AUTOSAR XML (schema 4-3-0)
package /ComponentTypes
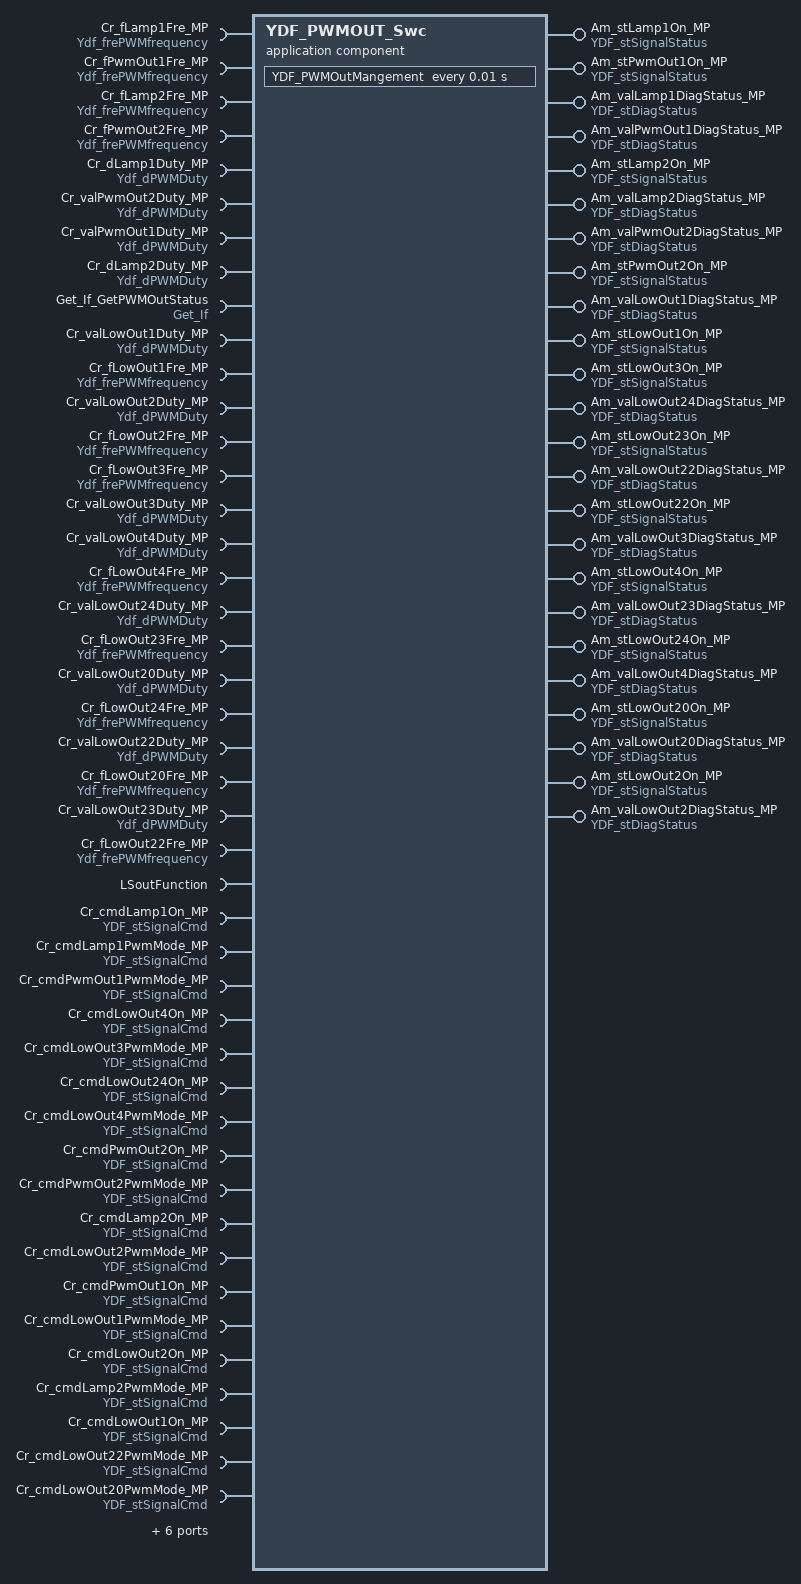
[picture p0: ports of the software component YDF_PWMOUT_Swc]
  application sw component type YDF_PWMOUT_Swc
    provide port Am_stLamp1On_MP: nonqueued-sender-com-spec{data-element=SignalStatus, init-value=0}, provided-interface=YDF_stSignalStatus
    8 x require port:
      Cr_fLamp1Fre_MP: nonqueued-receiver-com-spec{data-element=PWMfrequency, init-value=0}, required-interface=Ydf_frePWMfrequency
      Cr_fPwmOut1Fre_MP: nonqueued-receiver-com-spec{data-element=PWMfrequency, init-value=0}, required-interface=Ydf_frePWMfrequency
      Cr_fLamp2Fre_MP: nonqueued-receiver-com-spec{data-element=PWMfrequency, filter=data-filter-type=ALWAYS, init-value=0}, required-interface=Ydf_frePWMfrequency
      Cr_fPwmOut2Fre_MP: nonqueued-receiver-com-spec{data-element=PWMfrequency, init-value=0}, required-interface=Ydf_frePWMfrequency
      Cr_dLamp1Duty_MP: nonqueued-receiver-com-spec{data-element=PWMDuty, filter=data-filter-type=ALWAYS, init-value=0}, required-interface=Ydf_dPWMDuty
      Cr_valPwmOut2Duty_MP: nonqueued-receiver-com-spec{data-element=PWMDuty, filter=data-filter-type=ALWAYS, init-value=0}, required-interface=Ydf_dPWMDuty
      Cr_valPwmOut1Duty_MP: nonqueued-receiver-com-spec{data-element=PWMDuty, filter=data-filter-type=ALWAYS, init-value=0}, required-interface=Ydf_dPWMDuty
      Cr_dLamp2Duty_MP: nonqueued-receiver-com-spec{data-element=PWMDuty, filter=data-filter-type=ALWAYS, init-value=0}, required-interface=Ydf_dPWMDuty
    provide port Am_stPwmOut1On_MP: nonqueued-sender-com-spec{data-element=SignalStatus, init-value=0}, provided-interface=YDF_stSignalStatus
    provide port Am_valLamp1DiagStatus_MP: nonqueued-sender-com-spec{data-element=DiagStatus, init-value=0}, provided-interface=YDF_stDiagStatus
    provide port Am_valPwmOut1DiagStatus_MP: nonqueued-sender-com-spec{data-element=DiagStatus, init-value=0}, provided-interface=YDF_stDiagStatus
    require port Get_If_GetPWMOutStatus: required-interface=Get_If
      required-com-specs:
        Get_Ad_Result
        Get_io_inResult
        Get_BTS_OutResult
        Get_CAN_ActiveInf
        Icu_17_GtmCcu6_PWMIN_CH{1..4}
        Icu_17_GtmCcu6_PWMIN_PWMSCB1
        Icu_17_GtmCcu6_PWMIN_PWMSCB2
        Icu_17_GtmCcu6_PWMIN_LAMPSCB1
        Icu_17_GtmCcu6_PWMIN_LAMPSCB2
        Get_Bottom_Ver
        Get_SentData
        Get_Level_OutResult
        Get_PwmOrLevel_OutResult
        Get_Motor_OutResult
    4 x provide port:
      Am_stLamp2On_MP: nonqueued-sender-com-spec{data-element=SignalStatus, init-value=0}, provided-interface=YDF_stSignalStatus
      Am_valLamp2DiagStatus_MP: nonqueued-sender-com-spec{data-element=DiagStatus, init-value=0}, provided-interface=YDF_stDiagStatus
      Am_valPwmOut2DiagStatus_MP: nonqueued-sender-com-spec{data-element=DiagStatus, init-value=0}, provided-interface=YDF_stDiagStatus
      Am_stPwmOut2On_MP: nonqueued-sender-com-spec{data-element=SignalStatus, init-value=0}, provided-interface=YDF_stSignalStatus
    17 x require port:
      Cr_valLowOut1Duty_MP: nonqueued-receiver-com-spec{data-element=PWMDuty, filter=data-filter-type=ALWAYS, init-value=0}, required-interface=Ydf_dPWMDuty
      Cr_fLowOut1Fre_MP: nonqueued-receiver-com-spec{data-element=PWMfrequency, init-value=0}, required-interface=Ydf_frePWMfrequency
      Cr_valLowOut2Duty_MP: nonqueued-receiver-com-spec{data-element=PWMDuty, filter=data-filter-type=ALWAYS, init-value=0}, required-interface=Ydf_dPWMDuty
      Cr_fLowOut2Fre_MP: nonqueued-receiver-com-spec{data-element=PWMfrequency, init-value=0}, required-interface=Ydf_frePWMfrequency
      Cr_fLowOut3Fre_MP: nonqueued-receiver-com-spec{data-element=PWMfrequency, init-value=0}, required-interface=Ydf_frePWMfrequency
      Cr_valLowOut3Duty_MP: nonqueued-receiver-com-spec{data-element=PWMDuty, filter=data-filter-type=ALWAYS, init-value=0}, required-interface=Ydf_dPWMDuty
      Cr_valLowOut4Duty_MP: nonqueued-receiver-com-spec{data-element=PWMDuty, filter=data-filter-type=ALWAYS, init-value=0}, required-interface=Ydf_dPWMDuty
      Cr_fLowOut4Fre_MP: nonqueued-receiver-com-spec{data-element=PWMfrequency, init-value=0}, required-interface=Ydf_frePWMfrequency
      Cr_valLowOut24Duty_MP: nonqueued-receiver-com-spec{data-element=PWMDuty, filter=data-filter-type=ALWAYS, init-value=0}, required-interface=Ydf_dPWMDuty
      Cr_fLowOut23Fre_MP: nonqueued-receiver-com-spec{data-element=PWMfrequency, init-value=0}, required-interface=Ydf_frePWMfrequency
      Cr_valLowOut20Duty_MP: nonqueued-receiver-com-spec{data-element=PWMDuty, filter=data-filter-type=ALWAYS, init-value=0}, required-interface=Ydf_dPWMDuty
      Cr_fLowOut24Fre_MP: nonqueued-receiver-com-spec{data-element=PWMfrequency, init-value=0}, required-interface=Ydf_frePWMfrequency
      Cr_valLowOut22Duty_MP: nonqueued-receiver-com-spec{data-element=PWMDuty, filter=data-filter-type=ALWAYS, init-value=0}, required-interface=Ydf_dPWMDuty
      Cr_fLowOut20Fre_MP: nonqueued-receiver-com-spec{data-element=PWMfrequency, init-value=0}, required-interface=Ydf_frePWMfrequency
      Cr_valLowOut23Duty_MP: nonqueued-receiver-com-spec{data-element=PWMDuty, filter=data-filter-type=ALWAYS, init-value=0}, required-interface=Ydf_dPWMDuty
      Cr_fLowOut22Fre_MP: nonqueued-receiver-com-spec{data-element=PWMfrequency, init-value=0}, required-interface=Ydf_frePWMfrequency
      LSoutFunction: required-interface=LSoutFunction
        required-com-specs:
          Lowout{1..4}_Function
          Lowout20_Function
          Lowout{22..24}_Function
          Lowout_Lamp1_Function
          Lowout_Lamp2_Function
          Lowout_PWMOUT1_Function
          Lowout_PWMOUT2_Function
          Lowout{5..19}_Function
          Lowout21_Function
    16 x provide port:
      Am_valLowOut1DiagStatus_MP: nonqueued-sender-com-spec{data-element=DiagStatus, init-value=0}, provided-interface=YDF_stDiagStatus
      Am_stLowOut1On_MP: nonqueued-sender-com-spec{data-element=SignalStatus, init-value=0}, provided-interface=YDF_stSignalStatus
      Am_stLowOut3On_MP: nonqueued-sender-com-spec{data-element=SignalStatus, init-value=0}, provided-interface=YDF_stSignalStatus
      Am_valLowOut24DiagStatus_MP: nonqueued-sender-com-spec{data-element=DiagStatus, init-value=0}, provided-interface=YDF_stDiagStatus
      Am_stLowOut23On_MP: nonqueued-sender-com-spec{data-element=SignalStatus, init-value=0}, provided-interface=YDF_stSignalStatus
      Am_valLowOut22DiagStatus_MP: nonqueued-sender-com-spec{data-element=DiagStatus, init-value=0}, provided-interface=YDF_stDiagStatus
      Am_stLowOut22On_MP: nonqueued-sender-com-spec{data-element=SignalStatus, init-value=0}, provided-interface=YDF_stSignalStatus
      Am_valLowOut3DiagStatus_MP: nonqueued-sender-com-spec{data-element=DiagStatus, init-value=0}, provided-interface=YDF_stDiagStatus
      Am_stLowOut4On_MP: nonqueued-sender-com-spec{data-element=SignalStatus, init-value=0}, provided-interface=YDF_stSignalStatus
      Am_valLowOut23DiagStatus_MP: nonqueued-sender-com-spec{data-element=DiagStatus, init-value=0}, provided-interface=YDF_stDiagStatus
      Am_stLowOut24On_MP: nonqueued-sender-com-spec{data-element=SignalStatus, init-value=0}, provided-interface=YDF_stSignalStatus
      Am_valLowOut4DiagStatus_MP: nonqueued-sender-com-spec{data-element=DiagStatus, init-value=0}, provided-interface=YDF_stDiagStatus
      Am_stLowOut20On_MP: nonqueued-sender-com-spec{data-element=SignalStatus, init-value=0}, provided-interface=YDF_stSignalStatus
      Am_valLowOut20DiagStatus_MP: nonqueued-sender-com-spec{data-element=DiagStatus, init-value=0}, provided-interface=YDF_stDiagStatus
      Am_stLowOut2On_MP: nonqueued-sender-com-spec{data-element=SignalStatus, init-value=0}, provided-interface=YDF_stSignalStatus
      Am_valLowOut2DiagStatus_MP: nonqueued-sender-com-spec{data-element=DiagStatus, init-value=0}, provided-interface=YDF_stDiagStatus
    24 x require port, all with nonqueued-receiver-com-spec{data-element=SignalCmd, init-value=0}, required-interface=YDF_stSignalCmd:
      Cr_cmdLamp1On_MP
      Cr_cmdLamp1PwmMode_MP
      Cr_cmdPwmOut1PwmMode_MP
      Cr_cmdLowOut4On_MP
      Cr_cmdLowOut3PwmMode_MP
      Cr_cmdLowOut24On_MP
      Cr_cmdLowOut4PwmMode_MP
      Cr_cmdPwmOut2On_MP
      Cr_cmdPwmOut2PwmMode_MP
      Cr_cmdLamp2On_MP
      Cr_cmdLowOut2PwmMode_MP
      Cr_cmdPwmOut1On_MP
      Cr_cmdLowOut1PwmMode_MP
      Cr_cmdLowOut2On_MP
      Cr_cmdLamp2PwmMode_MP
      Cr_cmdLowOut1On_MP
      Cr_cmdLowOut22PwmMode_MP
      Cr_cmdLowOut20PwmMode_MP
      Cr_cmdLowOut23PwmMode_MP
      Cr_cmdLowOut24PwmMode_MP
      Cr_cmdLowOut20On_MP
      Cr_cmdLowOut22On_MP
      Cr_cmdLowOut23On_MP
      Cr_cmdLowOut3On_MP
    behavior YDF_PWMOUT_Swc_InternalBehavior
      timing event TMT_YDF_PWMOutMangement: start-on-event=YDF_PWMOutMangement, period=0.01
      runnable YDF_PWMOutMangement
        data-receive-point-by-arguments:
          48 x access:
            REC_Cr_dLamp1Duty_MP_PWMDuty: accessed-variable=Cr_dLamp1Duty_MP.PWMDuty
            REC_Cr_dLamp2Duty_MP_PWMDuty: accessed-variable=Cr_dLamp2Duty_MP.PWMDuty
            REC_Cr_fLamp1Fre_MP_PWMfrequency: accessed-variable=Cr_fLamp1Fre_MP.PWMfrequency
            REC_Cr_fLamp2Fre_MP_PWMfrequency: accessed-variable=Cr_fLamp2Fre_MP.PWMfrequency
            REC_Cr_fLowOut1Fre_MP_PWMfrequency: accessed-variable=Cr_fLowOut1Fre_MP.PWMfrequency
            REC_Cr_fLowOut20Fre_MP_PWMfrequency: accessed-variable=Cr_fLowOut20Fre_MP.PWMfrequency
            REC_Cr_fLowOut{22..24}Fre_MP_PWMfrequency: accessed-variable=Cr_fLowOut{22..24}Fre_MP.PWMfrequency
            REC_Cr_fLowOut{2..4}Fre_MP_PWMfrequency: accessed-variable=Cr_fLowOut{2..4}Fre_MP.PWMfrequency
            REC_Cr_fPwmOut1Fre_MP_PWMfrequency: accessed-variable=Cr_fPwmOut1Fre_MP.PWMfrequency
            REC_Cr_fPwmOut2Fre_MP_PWMfrequency: accessed-variable=Cr_fPwmOut2Fre_MP.PWMfrequency
            REC_Cr_valLowOut1Duty_MP_PWMDuty: accessed-variable=Cr_valLowOut1Duty_MP.PWMDuty
            REC_Cr_valLowOut20Duty_MP_PWMDuty: accessed-variable=Cr_valLowOut20Duty_MP.PWMDuty
            REC_Cr_valLowOut{22..24}Duty_MP_PWMDuty: accessed-variable=Cr_valLowOut{22..24}Duty_MP.PWMDuty
            REC_Cr_valLowOut{2..4}Duty_MP_PWMDuty: accessed-variable=Cr_valLowOut{2..4}Duty_MP.PWMDuty
            REC_Cr_valPwmOut1Duty_MP_PWMDuty: accessed-variable=Cr_valPwmOut1Duty_MP.PWMDuty
            REC_Cr_valPwmOut2Duty_MP_PWMDuty: accessed-variable=Cr_valPwmOut2Duty_MP.PWMDuty
            REC_Cr_cmdLamp1On_MP_SignalCmd: accessed-variable=Cr_cmdLamp1On_MP.SignalCmd
            REC_Cr_cmdLamp1PwmMode_MP_SignalCmd: accessed-variable=Cr_cmdLamp1PwmMode_MP.SignalCmd
            REC_Cr_cmdLamp2On_MP_SignalCmd: accessed-variable=Cr_cmdLamp2On_MP.SignalCmd
            REC_Cr_cmdLamp2PwmMode_MP_SignalCmd: accessed-variable=Cr_cmdLamp2PwmMode_MP.SignalCmd
            REC_Cr_cmdLowOut1On_MP_SignalCmd: accessed-variable=Cr_cmdLowOut1On_MP.SignalCmd
            REC_Cr_cmdLowOut1PwmMode_MP_SignalCmd: accessed-variable=Cr_cmdLowOut1PwmMode_MP.SignalCmd
            REC_Cr_cmdLowOut20On_MP_SignalCmd: accessed-variable=Cr_cmdLowOut20On_MP.SignalCmd
            REC_Cr_cmdLowOut20PwmMode_MP_SignalCmd: accessed-variable=Cr_cmdLowOut20PwmMode_MP.SignalCmd
            REC_Cr_cmdLowOut22On_MP_SignalCmd: accessed-variable=Cr_cmdLowOut22On_MP.SignalCmd
            REC_Cr_cmdLowOut22PwmMode_MP_SignalCmd: accessed-variable=Cr_cmdLowOut22PwmMode_MP.SignalCmd
            REC_Cr_cmdLowOut23On_MP_SignalCmd: accessed-variable=Cr_cmdLowOut23On_MP.SignalCmd
            REC_Cr_cmdLowOut23PwmMode_MP_SignalCmd: accessed-variable=Cr_cmdLowOut23PwmMode_MP.SignalCmd
            REC_Cr_cmdLowOut24On_MP_SignalCmd: accessed-variable=Cr_cmdLowOut24On_MP.SignalCmd
            REC_Cr_cmdLowOut24PwmMode_MP_SignalCmd: accessed-variable=Cr_cmdLowOut24PwmMode_MP.SignalCmd
            REC_Cr_cmdLowOut2On_MP_SignalCmd: accessed-variable=Cr_cmdLowOut2On_MP.SignalCmd
            REC_Cr_cmdLowOut2PwmMode_MP_SignalCmd: accessed-variable=Cr_cmdLowOut2PwmMode_MP.SignalCmd
            REC_Cr_cmdLowOut3On_MP_SignalCmd: accessed-variable=Cr_cmdLowOut3On_MP.SignalCmd
            REC_Cr_cmdLowOut3PwmMode_MP_SignalCmd: accessed-variable=Cr_cmdLowOut3PwmMode_MP.SignalCmd
            REC_Cr_cmdLowOut4On_MP_SignalCmd: accessed-variable=Cr_cmdLowOut4On_MP.SignalCmd
            REC_Cr_cmdLowOut4PwmMode_MP_SignalCmd: accessed-variable=Cr_cmdLowOut4PwmMode_MP.SignalCmd
            REC_Cr_cmdPwmOut1On_MP_SignalCmd: accessed-variable=Cr_cmdPwmOut1On_MP.SignalCmd
            REC_Cr_cmdPwmOut1PwmMode_MP_SignalCmd: accessed-variable=Cr_cmdPwmOut1PwmMode_MP.SignalCmd
            REC_Cr_cmdPwmOut2On_MP_SignalCmd: accessed-variable=Cr_cmdPwmOut2On_MP.SignalCmd
            REC_Cr_cmdPwmOut2PwmMode_MP_SignalCmd: accessed-variable=Cr_cmdPwmOut2PwmMode_MP.SignalCmd
        data-send-points:
          24 x access:
            SEND_Am_fLamp1On_MP_SignalStatus: accessed-variable=Am_stLamp1On_MP.SignalStatus
            SEND_Am_fLamp2On_MP_SignalStatus: accessed-variable=Am_stLamp2On_MP.SignalStatus
            SEND_Am_fLowOut1On_MP_SignalStatus: accessed-variable=Am_stLowOut1On_MP.SignalStatus
            SEND_Am_fLowOut20On_MP_SignalStatus: accessed-variable=Am_stLowOut20On_MP.SignalStatus
            SEND_Am_fLowOut{22..24}On_MP_SignalStatus: accessed-variable=Am_stLowOut{22..24}On_MP.SignalStatus
            SEND_Am_fLowOut{2..4}On_MP_SignalStatus: accessed-variable=Am_stLowOut{2..4}On_MP.SignalStatus
            SEND_Am_fPwmOut1On_MP_SignalStatus: accessed-variable=Am_stPwmOut1On_MP.SignalStatus
            SEND_Am_fPwmOut2On_MP_SignalStatus: accessed-variable=Am_stPwmOut2On_MP.SignalStatus
            SEND_Am_valLamp1DiagStatus_MP_DiagStatus: accessed-variable=Am_valLamp1DiagStatus_MP.DiagStatus
            SEND_Am_valLamp2DiagStatus_MP_DiagStatus: accessed-variable=Am_valLamp2DiagStatus_MP.DiagStatus
            SEND_Am_valLowOut1DiagStatus_MP_DiagStatus: accessed-variable=Am_valLowOut1DiagStatus_MP.DiagStatus
            SEND_Am_valLowOut20DiagStatus_MP_DiagStatus: accessed-variable=Am_valLowOut20DiagStatus_MP.DiagStatus
            SEND_Am_valLowOut{22..24}DiagStatus_MP_DiagStatus: accessed-variable=Am_valLowOut{22..24}DiagStatus_MP.DiagStatus
            SEND_Am_valLowOut{2..4}DiagStatus_MP_DiagStatus: accessed-variable=Am_valLowOut{2..4}DiagStatus_MP.DiagStatus
            SEND_Am_valPwmOut1DiagStatus_MP_DiagStatus: accessed-variable=Am_valPwmOut1DiagStatus_MP.DiagStatus
            SEND_Am_valPwmOut2DiagStatus_MP_DiagStatus: accessed-variable=Am_valPwmOut2DiagStatus_MP.DiagStatus
        13 x sync call:
          SC_Get_If_GetPWMOutStatus_Get_PwmOrLevel_OutResult: operation=Get_If_GetPWMOutStatus.Get_PwmOrLevel_OutResult
          SC_LSoutFunction_Lowout_Lamp1_Function: operation=LSoutFunction.Lowout_Lamp1_Function
          SC_LSoutFunction_Lowout_Lamp2_Function: operation=LSoutFunction.Lowout_Lamp2_Function
          SC_LSoutFunction_Lowout_PWMOUT1_Function: operation=LSoutFunction.Lowout_PWMOUT1_Function
          SC_LSoutFunction_Lowout_PWMOUT2_Function: operation=LSoutFunction.Lowout_PWMOUT2_Function
          SC_LSoutFunction_Lowout1_Function: operation=LSoutFunction.Lowout1_Function
          SC_LSoutFunction_Lowout20_Function: operation=LSoutFunction.Lowout20_Function
          SC_LSoutFunction_Lowout{22..24}_Function: operation=LSoutFunction.Lowout{22..24}_Function
          SC_LSoutFunction_Lowout{2..4}_Function: operation=LSoutFunction.Lowout{2..4}_Function
  swc implementation YDF_PWMOUT_Swc_Implementation: behavior=YDF_PWMOUT_Swc_InternalBehavior
